AUTOSAR XML (schema 314)
package /ComponentType
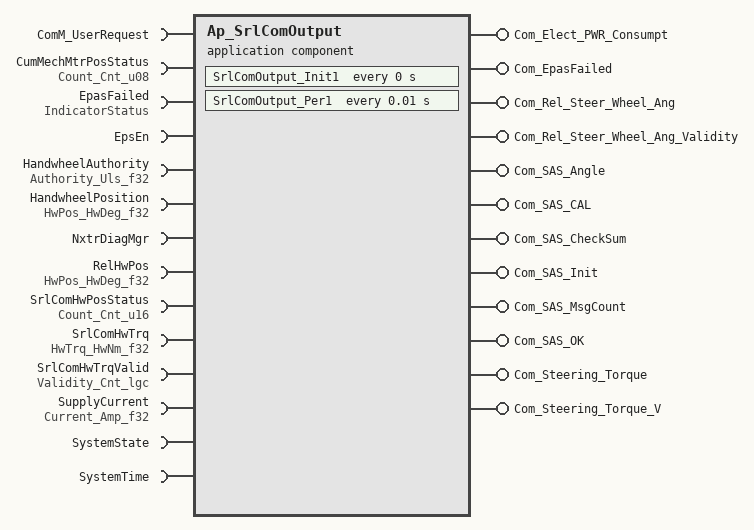
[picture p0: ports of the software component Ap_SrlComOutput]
  application software component type Ap_SrlComOutput
    12 x provide port:
      Com_Elect_PWR_Consumpt: unqueued-sender-com-spec{data-element=Cnt_u08, can-invalidate=false, init-value=C_Elect_PWR_Consumpt}, provided-interface=Com_Elect_PWR_Consumpt
      Com_EpasFailed: unqueued-sender-com-spec{data-element=Cnt_lgc, can-invalidate=false, init-value=C_EpasFailed}, provided-interface=Com_EpasFailed
      Com_Rel_Steer_Wheel_Ang: unqueued-sender-com-spec{data-element=Cnt_u16, can-invalidate=false, init-value=C_RELSTRWHLANGINIT_CNT_U16}, provided-interface=Com_Rel_Steer_Wheel_Ang
      Com_Rel_Steer_Wheel_Ang_Validity: unqueued-sender-com-spec{data-element=Cnt_lgc, can-invalidate=false, init-value=C_RELSTRWHLANGVALIDINIT_CNT_LGC}, provided-interface=Com_Rel_Steer_Wheel_Ang_Validity
      Com_SAS_Angle: unqueued-sender-com-spec{data-element=Cnt_u16, can-invalidate=false, init-value=C_SAS_Angle}, provided-interface=Com_SAS_Angle
      Com_SAS_CAL: unqueued-sender-com-spec{data-element=Cnt_lgc, can-invalidate=false, init-value=C_SAS_CAL}, provided-interface=Com_SAS_CAL
      Com_SAS_CheckSum: unqueued-sender-com-spec{data-element=Cnt_u08, can-invalidate=false, init-value=C_SAS_CheckSum}, provided-interface=Com_SAS_CheckSum
      Com_SAS_Init: unqueued-sender-com-spec{data-element=Cnt_lgc, can-invalidate=false, init-value=C_SAS_Init}, provided-interface=Com_SAS_Init
      Com_SAS_MsgCount: unqueued-sender-com-spec{data-element=Cnt_u08, can-invalidate=false, init-value=C_SAS_MsgCount}, provided-interface=Com_SAS_MsgCount
      Com_SAS_OK: unqueued-sender-com-spec{data-element=Cnt_lgc, can-invalidate=false, init-value=C_SAS_OK}, provided-interface=Com_SAS_OK
      Com_Steering_Torque: unqueued-sender-com-spec{data-element=Cnt_u08, can-invalidate=false, init-value=C_Steering_Torque}, provided-interface=Com_Steering_Torque
      Com_Steering_Torque_V: unqueued-sender-com-spec{data-element=Cnt_lgc, can-invalidate=false, init-value=C_Steering_Torque_V}, provided-interface=Com_Steering_Torque_V
    14 x require port:
      ComM_UserRequest: required-com-specs=[GetCurrentComMode, GetMaxComMode, GetRequestedComMode, RequestComMode], required-interface=ComM_UserRequest
      CumMechMtrPosStatus: unqueued-receiver-com-spec{data-element=Cnt_u08, init-value=D_ZERO_CNT_U8}, required-interface=Count_Cnt_u08
      EpasFailed: client-com-spec=GetIndicatorStatus, required-interface=IndicatorStatus
      EpsEn: client-com-spec=OP_GET, required-interface=EpsEn
      HandwheelAuthority: unqueued-receiver-com-spec{data-element=Uls_f32, init-value=D_ZERO_ULS_F32}, required-interface=Authority_Uls_f32
      HandwheelPosition: unqueued-receiver-com-spec{data-element=HwDeg_f32, init-value=D_ZERO_ULS_F32}, required-interface=HwPos_HwDeg_f32
      NxtrDiagMgr: required-com-specs=[GetNTCActive, GetNTCFailed, GetNTCStatus, SetNTCStatus], required-interface=NxtrDiagMgr
      RelHwPos: unqueued-receiver-com-spec{data-element=HwDeg_f32, init-value=D_ZERO_ULS_F32}, required-interface=HwPos_HwDeg_f32
      SrlComHwPosStatus: unqueued-receiver-com-spec{data-element=Cnt_u16, init-value=D_ZERO_CNT_U16}, required-interface=Count_Cnt_u16
      SrlComHwTrq: unqueued-receiver-com-spec{data-element=HwNm_f32, init-value=D_ZERO_ULS_F32}, required-interface=HwTrq_HwNm_f32
      SrlComHwTrqValid: unqueued-receiver-com-spec{data-element=Cnt_lgc, init-value=D_FALSE_CNT_LGC}, required-interface=Validity_Cnt_lgc
      SupplyCurrent: unqueued-receiver-com-spec{data-element=Amp_f32, init-value=D_ZERO_ULS_F32}, required-interface=Current_Amp_f32
      SystemState: required-interface=SystemState
      SystemTime: required-interface=SystemTime
        required-com-specs:
          DtrmnElapsedTime_mS_u16
          DtrmnElapsedTime_mS_u32
          DtrmnElapsedTime_uS_u16
          DtrmnElapsedTime_uS_u32
          GetSystemTime_mS_u32
          GetSystemTime_uS_u32
  internal behavior Ap_SrlComOutput_InternalBehavior: component=Ap_SrlComOutput
    timing event SrlComOutput_Init1_InitEvent: start-on-event=SrlComOutput_Init1, period=0
    timing event TMT_SrlComOutput_Per1: start-on-event=SrlComOutput_Per1, period=0.01
    port-api-options:
      enable-take-address=false, indirect-api=false, port=Com_Elect_PWR_Consumpt
      enable-take-address=false, indirect-api=false, port=Com_EpasFailed
      enable-take-address=false, indirect-api=false, port=Com_Rel_Steer_Wheel_Ang
      enable-take-address=false, indirect-api=false, port=Com_Rel_Steer_Wheel_Ang_Validity
      enable-take-address=false, indirect-api=false, port=Com_SAS_Angle
      enable-take-address=false, indirect-api=false, port=Com_SAS_CAL
      enable-take-address=false, indirect-api=false, port=Com_SAS_CheckSum
      enable-take-address=false, indirect-api=false, port=Com_SAS_Init
      enable-take-address=false, indirect-api=false, port=Com_SAS_MsgCount
      enable-take-address=false, indirect-api=false, port=Com_SAS_OK
      enable-take-address=false, indirect-api=false, port=Com_Steering_Torque
      enable-take-address=false, indirect-api=false, port=Com_Steering_Torque_V
      enable-take-address=false, indirect-api=false, port=ComM_UserRequest
      enable-take-address=false, indirect-api=false, port=CumMechMtrPosStatus
      enable-take-address=false, indirect-api=false, port=EpasFailed
      enable-take-address=false, indirect-api=false, port=EpsEn
      enable-take-address=false, indirect-api=false, port=HandwheelAuthority
      enable-take-address=false, indirect-api=false, port=HandwheelPosition
      enable-take-address=false, indirect-api=false, port=NxtrDiagMgr
      enable-take-address=false, indirect-api=false, port=RelHwPos
      enable-take-address=false, indirect-api=false, port=SrlComHwPosStatus
      enable-take-address=false, indirect-api=false, port=SrlComHwTrq
      enable-take-address=false, indirect-api=false, port=SrlComHwTrqValid
      enable-take-address=false, indirect-api=false, port=SupplyCurrent
      enable-take-address=false, indirect-api=false, port=SystemState
      enable-take-address=false, indirect-api=false, port=SystemTime
    runnable SrlComOutput_Init1
      sync call SC_ComM_UserRequest_RequestComMode: operation=ComM_UserRequest.RequestComMode, timeout=0
    runnable SrlComOutput_Per1
      8 x data read access:
        READ_CumMechMtrPosStatus_Cnt_u08: data-element=CumMechMtrPosStatus.Cnt_u08
        READ_HandwheelAuthority_Uls_f32: data-element=HandwheelAuthority.Uls_f32
        READ_HandwheelPosition_HwDeg_f32: data-element=HandwheelPosition.HwDeg_f32
        READ_RelHwPos_HwDeg_f32: data-element=RelHwPos.HwDeg_f32
        READ_SrlComHwPosStatus_Cnt_u16: data-element=SrlComHwPosStatus.Cnt_u16
        READ_SrlComHwTrq_HwNm_f32: data-element=SrlComHwTrq.HwNm_f32
        READ_SrlComHwTrqValid_Cnt_lgc: data-element=SrlComHwTrqValid.Cnt_lgc
        READ_SupplyCurrent_Amp_f32: data-element=SupplyCurrent.Amp_f32
      12 x data write access:
        WRITE_Com_Elect_PWR_Consumpt_Cnt_u08: data-element=Com_Elect_PWR_Consumpt.Cnt_u08
        WRITE_Com_EpasFailed_Cnt_lgc: data-element=Com_EpasFailed.Cnt_lgc
        WRITE_Com_Rel_Steer_Wheel_Ang_Cnt_u16: data-element=Com_Rel_Steer_Wheel_Ang.Cnt_u16
        WRITE_Com_Rel_Steer_Wheel_Ang_Validity_Cnt_lgc: data-element=Com_Rel_Steer_Wheel_Ang_Validity.Cnt_lgc
        WRITE_Com_SAS_Angle_Cnt_u16: data-element=Com_SAS_Angle.Cnt_u16
        WRITE_Com_SAS_CAL_Cnt_lgc: data-element=Com_SAS_CAL.Cnt_lgc
        WRITE_Com_SAS_CheckSum_Cnt_u08: data-element=Com_SAS_CheckSum.Cnt_u08
        WRITE_Com_SAS_Init_Cnt_lgc: data-element=Com_SAS_Init.Cnt_lgc
        WRITE_Com_SAS_MsgCount_Cnt_u08: data-element=Com_SAS_MsgCount.Cnt_u08
        WRITE_Com_SAS_OK_Cnt_lgc: data-element=Com_SAS_OK.Cnt_lgc
        WRITE_Com_Steering_Torque_Cnt_u08: data-element=Com_Steering_Torque.Cnt_u08
        WRITE_Com_Steering_Torque_V_Cnt_lgc: data-element=Com_Steering_Torque_V.Cnt_lgc
      6 x sync call, all with timeout=0:
        SC_ComM_UserRequest_RequestComMode: operation=ComM_UserRequest.RequestComMode
        SC_EpasFailed_GetIndicatorStatus: operation=EpasFailed.GetIndicatorStatus
        SC_EpsEn_OP_GET: operation=EpsEn.OP_GET
        SC_NxtrDiagMgr_GetNTCFailed: operation=NxtrDiagMgr.GetNTCFailed
        SC_SystemTime_DtrmnElapsedTime_mS_u16: operation=SystemTime.DtrmnElapsedTime_mS_u16
        SC_SystemTime_GetSystemTime_mS_u32: operation=SystemTime.GetSystemTime_mS_u32
  swc implementation Ap_SrlComOutput_Implementation: behavior=Ap_SrlComOutput_InternalBehavior
    code-descriptors:
      code Code: type=SRC
